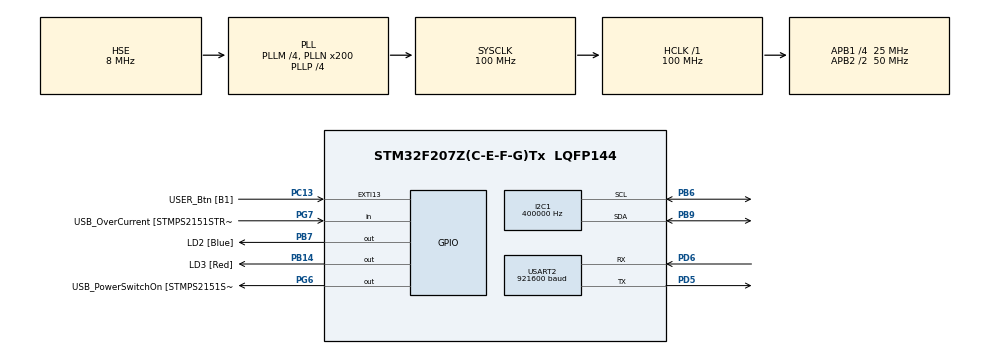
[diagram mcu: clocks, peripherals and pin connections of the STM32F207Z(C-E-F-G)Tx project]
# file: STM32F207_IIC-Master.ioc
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Dma.I2C1_RX.0.Direction=DMA_PERIPH_TO_MEMORY
Dma.I2C1_RX.0.FIFOMode=DMA_FIFOMODE_DISABLE
Dma.I2C1_RX.0.Instance=DMA1_Stream0
Dma.I2C1_RX.0.MemDataAlignment=DMA_MDATAALIGN_BYTE
Dma.I2C1_RX.0.MemInc=DMA_MINC_ENABLE
Dma.I2C1_RX.0.Mode=DMA_NORMAL
Dma.I2C1_RX.0.PeriphDataAlignment=DMA_PDATAALIGN_BYTE
Dma.I2C1_RX.0.PeriphInc=DMA_PINC_DISABLE
Dma.I2C1_RX.0.Priority=DMA_PRIORITY_VERY_HIGH
Dma.I2C1_TX.1.Direction=DMA_MEMORY_TO_PERIPH
Dma.I2C1_TX.1.FIFOMode=DMA_FIFOMODE_DISABLE
Dma.I2C1_TX.1.Instance=DMA1_Stream7
Dma.I2C1_TX.1.MemDataAlignment=DMA_MDATAALIGN_BYTE
Dma.I2C1_TX.1.MemInc=DMA_MINC_ENABLE
Dma.I2C1_TX.1.Mode=DMA_NORMAL
Dma.I2C1_TX.1.PeriphDataAlignment=DMA_PDATAALIGN_BYTE
Dma.I2C1_TX.1.PeriphInc=DMA_PINC_DISABLE
Dma.I2C1_TX.1.Priority=DMA_PRIORITY_VERY_HIGH
Dma.Request0=I2C1_RX
Dma.Request1=I2C1_TX
Dma.Request2=USART2_RX
Dma.Request3=USART2_TX
Dma.USART2_RX.2.Direction=DMA_PERIPH_TO_MEMORY
Dma.USART2_RX.2.FIFOMode=DMA_FIFOMODE_DISABLE
Dma.USART2_RX.2.Instance=DMA1_Stream5
Dma.USART2_RX.2.MemDataAlignment=DMA_MDATAALIGN_BYTE
Dma.USART2_RX.2.MemInc=DMA_MINC_ENABLE
Dma.USART2_RX.2.Mode=DMA_NORMAL
Dma.USART2_RX.2.PeriphDataAlignment=DMA_PDATAALIGN_BYTE
Dma.USART2_RX.2.PeriphInc=DMA_PINC_DISABLE
Dma.USART2_RX.2.Priority=DMA_PRIORITY_VERY_HIGH
Dma.USART2_TX.3.Direction=DMA_MEMORY_TO_PERIPH
Dma.USART2_TX.3.FIFOMode=DMA_FIFOMODE_DISABLE
Dma.USART2_TX.3.Instance=DMA1_Stream6
Dma.USART2_TX.3.MemDataAlignment=DMA_MDATAALIGN_BYTE
Dma.USART2_TX.3.MemInc=DMA_MINC_ENABLE
Dma.USART2_TX.3.Mode=DMA_NORMAL
Dma.USART2_TX.3.PeriphDataAlignment=DMA_PDATAALIGN_BYTE
Dma.USART2_TX.3.PeriphInc=DMA_PINC_DISABLE
Dma.USART2_TX.3.Priority=DMA_PRIORITY_HIGH
I2C1.ClockSpeed=400000
I2C1.I2C_Mode=I2C_Fast
I2C1.OwnAddress=0x07
Mcu.Family=STM32F2
Mcu.Name=STM32F207Z(C-E-F-G)Tx
Mcu.Package=LQFP144
NVIC.DMA1_Stream0_IRQn=true\:0\:0\:false\:false\:true\:false
NVIC.DMA1_Stream5_IRQn=true\:0\:0\:false\:false\:true\:false
NVIC.DMA1_Stream6_IRQn=true\:0\:0\:false\:false\:true\:false
NVIC.DMA1_Stream7_IRQn=true\:0\:0\:false\:false\:true\:false
NVIC.I2C1_ER_IRQn=true\:0\:0\:false\:false\:true\:true
NVIC.I2C1_EV_IRQn=true\:0\:0\:false\:false\:true\:true
NVIC.PVD_IRQn=true\:0\:0\:false\:false\:true\:true
NVIC.PriorityGroup=NVIC_PRIORITYGROUP_4
NVIC.USART2_IRQn=true\:0\:0\:false\:false\:true\:true
PA1.GPIO_Label=RMII_REF_CLK [LAN8742A-CZ-TR_REFCLK0]
PA1.Signal=ETH_REF_CLK
PA10.GPIO_Label=USB_ID
PA10.Signal=USB_OTG_FS_ID
PA11.GPIO_Label=USB_DM
PA11.Signal=USB_OTG_FS_DM
PA12.GPIO_Label=USB_DP
PA12.Signal=USB_OTG_FS_DP
PA13.GPIO_Label=TMS
PA13.Mode=Serial_Wire
PA13.Signal=SYS_JTMS-SWDIO
PA14.GPIO_Label=TCK
PA14.Mode=Serial_Wire
PA14.Signal=SYS_JTCK-SWCLK
PA2.GPIO_Label=RMII_MDIO [LAN8742A-CZ-TR_MDIO]
PA2.Signal=ETH_MDIO
PA7.GPIO_Label=RMII_CRS_DV [LAN8742A-CZ-TR_CRS_DV]
PA7.Signal=ETH_CRS_DV
PA8.GPIO_Label=USB_SOF [TP1]
PA8.Signal=USB_OTG_FS_SOF
PA9.GPIO_Label=USB_VBUS
PA9.Signal=USB_OTG_FS_VBUS
PB13.GPIO_Label=RMII_TXD1 [LAN8742A-CZ-TR_TXD1]
PB13.Signal=ETH_TXD1
PB14.GPIO_Label=LD3 [Red]
PB14.Signal=GPIO_Output
PB3.GPIO_Label=SWO
PB3.Signal=SYS_JTDO-SWO
PB6.Mode=I2C
PB6.Signal=I2C1_SCL
PB7.GPIO_Label=LD2 [Blue]
PB7.Signal=GPIO_Output
PB9.Mode=I2C
PB9.Signal=I2C1_SDA
PC1.GPIO_Label=RMII_MDC [LAN8742A-CZ-TR_MDC]
PC1.Signal=ETH_MDC
PC13.GPIO_Label=USER_Btn [B1]
PC13.Signal=GPXTI13
PC14-OSC32_IN.Signal=RCC_OSC32_IN
PC15-OSC32_OUT.Signal=RCC_OSC32_OUT
PC4.GPIO_Label=RMII_RXD0 [LAN8742A-CZ-TR_RXD0]
PC4.Signal=ETH_RXD0
PC5.GPIO_Label=RMII_RXD1 [LAN8742A-CZ-TR_RXD1]
PC5.Signal=ETH_RXD1
PD5.Mode=Asynchronous
PD5.Signal=USART2_TX
PD6.Mode=Asynchronous
PD6.Signal=USART2_RX
PD8.GPIO_Label=STLK_RX [STM32F103CBT6_PA3]
PD8.Signal=USART3_TX
PD9.GPIO_Label=STLK_TX [STM32F103CBT6_PA2]
PD9.Signal=USART3_RX
PG11.GPIO_Label=RMII_TX_EN [LAN8742A-CZ-TR_TXEN]
PG11.Signal=ETH_TX_EN
PG13.GPIO_Label=RMII_TXD0 [LAN8742A-CZ-TR_TXD0]
PG13.Signal=ETH_TXD0
PG6.GPIO_Label=USB_PowerSwitchOn [STMPS2151STR_EN]
PG6.Signal=GPIO_Output
PG7.GPIO_Label=USB_OverCurrent [STMPS2151STR_FAULT]
PG7.Signal=GPIO_Input
PH0-OSC_IN.GPIO_Label=MCO [STM32F103CBT6_PA8]
PH0-OSC_IN.Mode=HSE-External-Oscillator
PH0-OSC_IN.Signal=RCC_OSC_IN
PH1-OSC_OUT.Mode=HSE-External-Oscillator
PH1-OSC_OUT.Signal=RCC_OSC_OUT
ProjectManager.HeapSize=0x200
ProjectManager.StackSize=0x400
ProjectManager.TargetToolchain=MDK-ARM V5
RCC.48MHZClocksFreq_Value=100000000
RCC.AHBFreq_Value=100000000
RCC.APB1CLKDivider=RCC_HCLK_DIV4
RCC.APB1Freq_Value=25000000
RCC.APB1TimFreq_Value=50000000
RCC.APB2CLKDivider=RCC_HCLK_DIV2
RCC.APB2Freq_Value=50000000
RCC.APB2TimFreq_Value=100000000
RCC.CortexFreq_Value=100000000
RCC.HCLKFreq_Value=100000000
RCC.HSE_VALUE=8000000
RCC.HSI_VALUE=16000000
RCC.LSE_VALUE=32768
RCC.PLLM=4
RCC.PLLMUL=RCC_PLL_MUL9
RCC.PLLN=200
RCC.PLLP=RCC_PLLP_DIV4
RCC.PLLSourceVirtual=RCC_PLLSOURCE_HSE
RCC.PRESCALERUSB=RCC_USBCLKSOURCE_PLL_DIV1_5
RCC.SYSCLKFreq_VALUE=100000000
RCC.SYSCLKSource=RCC_SYSCLKSOURCE_PLLCLK
RCC.SYSCLKSourceVirtual=RCC_SYSCLKSOURCE_PLLCLK
RCC.USBFreq_Value=48000000
RCC.VCOOutputFreq_Value=400000000
USART2.BaudRate=921600
USART2.OverSampling=UART_OVERSAMPLING_16
USART2.VirtualMode=VM_ASYNC
board=NUCLEO-F207ZG

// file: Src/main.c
/**
  ******************************************************************************
  * @file           : main.c
  * @brief          : Main program body
  ******************************************************************************
  ** This notice applies to any and all portions of this file
  * that are not between comment pairs USER CODE BEGIN and
  * USER CODE END. Other portions of this file, whether
  * inserted by the user or by software development tools
  * are owned by their respective copyright owners.
  *
  * COPYRIGHT(c) 2018 STMicroelectronics
  *
  * Redistribution and use in source and binary forms, with or without modification,
  * are permitted provided that the following conditions are met:
  *   1. Redistributions of source code must retain the above copyright notice,
  *      this list of conditions and the following disclaimer.
  *   2. Redistributions in binary form must reproduce the above copyright notice,
  *      this list of conditions and the following disclaimer in the documentation
  *      and/or other materials provided with the distribution.
  *   3. Neither the name of STMicroelectronics nor the names of its contributors
  *      may be used to endorse or promote products derived from this software
  *      without specific prior written permission.
  *
  * THIS SOFTWARE IS PROVIDED BY THE COPYRIGHT HOLDERS AND CONTRIBUTORS "AS IS"
  * AND ANY EXPRESS OR IMPLIED WARRANTIES, INCLUDING, BUT NOT LIMITED TO, THE
  * IMPLIED WARRANTIES OF MERCHANTABILITY AND FITNESS FOR A PARTICULAR PURPOSE ARE
  * DISCLAIMED. IN NO EVENT SHALL THE COPYRIGHT HOLDER OR CONTRIBUTORS BE LIABLE
  * FOR ANY DIRECT, INDIRECT, INCIDENTAL, SPECIAL, EXEMPLARY, OR CONSEQUENTIAL
  * DAMAGES (INCLUDING, BUT NOT LIMITED TO, PROCUREMENT OF SUBSTITUTE GOODS OR
  * SERVICES; LOSS OF USE, DATA, OR PROFITS; OR BUSINESS INTERRUPTION) HOWEVER
  * CAUSED AND ON ANY THEORY OF LIABILITY, WHETHER IN CONTRACT, STRICT LIABILITY,
  * OR TORT (INCLUDING NEGLIGENCE OR OTHERWISE) ARISING IN ANY WAY OUT OF THE USE
  * OF THIS SOFTWARE, EVEN IF ADVISED OF THE POSSIBILITY OF SUCH DAMAGE.
  *
  ******************************************************************************
  */
#include "main.h"
#include "stm32f2xx_hal.h"
#include "dma.h"
#include "i2c.h"
#include "usart.h"
#include "gpio.h"

/* USER CODE BEGIN Includes */
#include "stdio.h"
#include "string.h"
#include "UsartCommandProc.h"
#include "I2CProc.h"
/* USER CODE END Includes */

/* USER CODE BEGIN PV */
/* Private variables ---------------------------------------------------------*/

/* USER CODE END PV */

void SystemClock_Config(void);

/* USER CODE BEGIN PFP */
/* Private function prototypes -----------------------------------------------*/

/* USER CODE END PFP */

/* USER CODE BEGIN 0 */

struct WorkMode __workMode;

/* USER CODE END 0 */

int main(void)
{
  /* USER CODE BEGIN 1 */
//	HAL_Delay(100);
  /* USER CODE END 1 */

  /* MCU Configuration----------------------------------------------------------*/

  /* Reset of all peripherals, Initializes the Flash interface and the Systick. */
  HAL_Init();

  /* Configure the system clock */
  SystemClock_Config();

  /* Initialize all configured peripherals */
  MX_GPIO_Init();
  MX_DMA_Init();
  MX_I2C1_Init();
  MX_USART2_UART_Init();
  /* USER CODE BEGIN 2 */
  UsartInit();

  printf("STM32F207 Ready!\r\n");
  /* USER CODE END 2 */

  /* Infinite loop */
  while (1)
  {

  /* USER CODE BEGIN 3 */
	UserCommandExitCheck();
	I2CWork(__workMode.workMode, __workMode.I2CSlaveNum, __workMode.I2CSlaveAddr);
  }
  /* USER CODE END 3 */

}

void SystemClock_Config(void)
{

  RCC_OscInitTypeDef RCC_OscInitStruct;
  RCC_ClkInitTypeDef RCC_ClkInitStruct;

    /**Initializes the CPU, AHB and APB busses clocks
    */
  RCC_OscInitStruct.OscillatorType = RCC_OSCILLATORTYPE_HSE;
  RCC_OscInitStruct.HSEState = RCC_HSE_ON;
  RCC_OscInitStruct.PLL.PLLState = RCC_PLL_ON;
  RCC_OscInitStruct.PLL.PLLSource = RCC_PLLSOURCE_HSE;
  RCC_OscInitStruct.PLL.PLLM = 4;
  RCC_OscInitStruct.PLL.PLLN = 200;
  RCC_OscInitStruct.PLL.PLLP = RCC_PLLP_DIV4;
  RCC_OscInitStruct.PLL.PLLQ = 4;
  if (HAL_RCC_OscConfig(&RCC_OscInitStruct) != HAL_OK)
  {
    _Error_Handler(__FILE__, __LINE__);
  }

    /**Initializes the CPU, AHB and APB busses clocks
    */
  RCC_ClkInitStruct.ClockType = RCC_CLOCKTYPE_HCLK|RCC_CLOCKTYPE_SYSCLK
                              |RCC_CLOCKTYPE_PCLK1|RCC_CLOCKTYPE_PCLK2;
  RCC_ClkInitStruct.SYSCLKSource = RCC_SYSCLKSOURCE_PLLCLK;
  RCC_ClkInitStruct.AHBCLKDivider = RCC_SYSCLK_DIV1;
  RCC_ClkInitStruct.APB1CLKDivider = RCC_HCLK_DIV4;
  RCC_ClkInitStruct.APB2CLKDivider = RCC_HCLK_DIV2;

  if (HAL_RCC_ClockConfig(&RCC_ClkInitStruct, FLASH_LATENCY_3) != HAL_OK)
  {
    _Error_Handler(__FILE__, __LINE__);
  }

    /**Configure the Systick interrupt time
    */
  HAL_SYSTICK_Config(HAL_RCC_GetHCLKFreq()/1000);

    /**Configure the Systick
    */
  HAL_SYSTICK_CLKSourceConfig(SYSTICK_CLKSOURCE_HCLK);

  /* SysTick_IRQn interrupt configuration */
  HAL_NVIC_SetPriority(SysTick_IRQn, 0, 0);
}

void _Error_Handler(char *file, int line)
{
  while(1)
  {
  }
}

#ifdef  USE_FULL_ASSERT
/**
  * @brief  Reports the name of the source file and the source line number
  *         where the assert_param error has occurred.
  * @param  file: pointer to the source file name
  * @param  line: assert_param error line source number
  * @retval None
  */
void assert_failed(uint8_t* file, uint32_t line)
{
  /* USER CODE BEGIN 6 */
	printf("Wrong parameters value: file %s on line %d\r\n", file, line);
  /* User can add his own implementation to report the file name and line number,
    ex: printf("Wrong parameters value: file %s on line %d\r\n", file, line) */
  /* USER CODE END 6 */
}
#endif /* USE_FULL_ASSERT */

/************************ (C) COPYRIGHT STMicroelectronics *****END OF FILE****/
